# R7FA2A2AD register map
Vendor: Renesas Electronics Corporation; Series: RA2A2; File version: 1.20.02
CPU: CM23 r1p0, little endian, MPU, no FPU, VTOR, 2 interrupt priority bits, 32 interrupts
Registers are 8-bit, read-write, reset 0x0 unless marked. A register's access mark holds for its fields unless they carry their own. Offsets are from the block's base; [hi:lo] are bit positions; {n}, {i} and the like mark numbered series.

## IIC0WU — Inter,Integrated Circuit 0 Wake,up Unit
Base 0x40053014
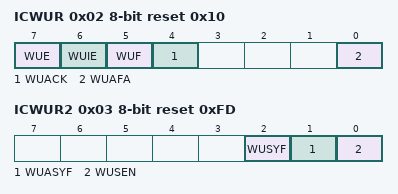
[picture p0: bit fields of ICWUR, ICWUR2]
0x02 ICWUR reset 0x10 — I2C Bus Wakeup Unit Register
  [7] WUE — Wakeup Function Enable
  [6] WUIE — Wakeup Interrupt Request Enable
  [5] WUF — Wakeup Event Occurrence Flag
  [4] WUACK — ACK Bit for Wakeup Mode
  [0] WUAFA — Wakeup Analog Filter Additional Selection
0x03 ICWUR2 reset 0xFD — I2C Bus Wakeup Unit Register 2
  [2] WUSYF ro — Wakeup Function Synchronous Operation Status Flag
  [1] WUASYF ro — Wakeup Function Asynchronous Operation Status Flag
  [0] WUSEN — Wakeup Function Synchronous Enable

## DOC — Data Operation Circuit
Base 0x40054100
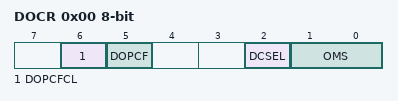
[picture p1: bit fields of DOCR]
0x00 DOCR — DOC Control Register
  [6] DOPCFCL — DOPCF Clear
  [5] DOPCF ro — DOC Flag
  [2] DCSEL — Detection Condition Select
  [1:0] OMS — Operating Mode Select
0x02 DODIR 16-bit — DOC Data Input Register
0x04 DODSR 16-bit — DOC Data Setting Register

## SPI0 — Serial Peripheral Interface
Base 0x40072000
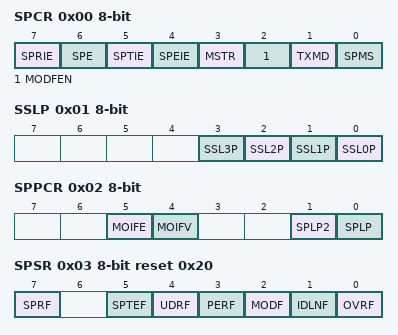
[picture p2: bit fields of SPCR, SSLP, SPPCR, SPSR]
0x00 SPCR — SPI Control Register
  [7] SPRIE — SPI Receive Buffer Full Interrupt Enable
  [6] SPE — SPI Function Enable
  [5] SPTIE — Transmit Buffer Empty Interrupt Enable
  [4] SPEIE — SPI Error Interrupt Enable
  [3] MSTR — SPI Master/Slave Mode Select
  [2] MODFEN — Mode Fault Error Detection Enable
  [1] TXMD — Communications Operating Mode Select
  [0] SPMS — SPI Mode Select
0x01 SSLP — SPI Slave Select Polarity Register
  [n] SSL{n}P (n=0..3) — SSLn{n} Signal Polarity Setting
0x02 SPPCR — SPI Pin Control Register
  [5] MOIFE — MOSI Idle Value Fixing Enable
  [4] MOIFV — MOSI Idle Fixed Value
  [1] SPLP2 — SPI Loopback 2
  [0] SPLP — SPI Loopback
0x03 SPSR reset 0x20 — SPI Status Register
  [7] SPRF — SPI Receive Buffer Full Flag
  [5] SPTEF — SPI Transmit Buffer Empty Flag
  [4] UDRF — Underrun Error Flag
  [3] PERF — Parity Error Flag
  [2] MODF — Mode Fault Error Flag
  [1] IDLNF ro — SPI Idle Flag
  [0] OVRF — Overrun Error Flag
0x04 SPDR 32-bit — SPI Data Register
0x04 SPDR_HA 16-bit (alternate view of SPDR) — SPI Data Register
0x04 SPDR_BY (alternate view of SPDR) — SPI Data Register
0x0A SPBR reset 0xFF — SPI Bit Rate Register
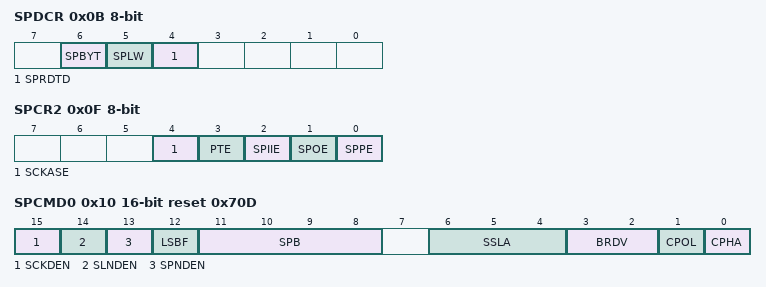
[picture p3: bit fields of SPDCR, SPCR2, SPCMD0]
0x0B SPDCR — SPI Data Control Register
  [6] SPBYT — SPI Byte Access Specification
  [5] SPLW — SPI Word Access/Halfword Access Specification
  [4] SPRDTD — SPI Receive/Transmit Data Select
0x0C SPCKD — SPI Clock Delay Register
  [2:0] SCKDL — RSPCK Delay Setting
0x0D SSLND — SPI Slave Select Negation Delay Register
  [2:0] SLNDL — SSL Negation Delay Setting
0x0E SPND — SPI Next,Access Delay Register
  [2:0] SPNDL — SPI Next,Access Delay Setting
0x0F SPCR2 — SPI Control Register 2
  [4] SCKASE — RSPCK Auto,Stop Function Enable
  [3] PTE — Parity Self,Testing
  [2] SPIIE — SPI Idle Interrupt Enable
  [1] SPOE — Parity Mode
  [0] SPPE — Parity Enable
0x10 SPCMD0 16-bit reset 0x70D — SPI Command Register 0
  [15] SCKDEN — RSPCK Delay Setting Enable
  [14] SLNDEN — SSL Negation Delay Setting Enable
  [13] SPNDEN — SPI Next,Access Delay Enable
  [12] LSBF — SPI LSB First
  [11:8] SPB — SPI Data Length Setting
  [6:4] SSLA — SSL Signal Assertion Setting
  [3:2] BRDV — Bit Rate Division Setting
  [1] CPOL — RSPCK Polarity Setting
  [0] CPHA — RSPCK Phase Setting

## CRC — Cyclic Redundancy Check Calculator
Base 0x40074000
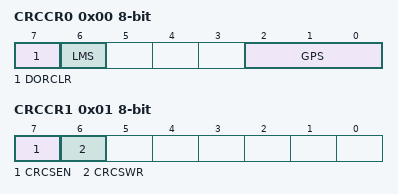
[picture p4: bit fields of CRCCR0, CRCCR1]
0x00 CRCCR0 — CRC Control Register 0
  [7] DORCLR wo — CRCDOR/CRCDOR_HA/CRCDOR_BY Register Clear
  [6] LMS — CRC Calculation Switching
  [2:0] GPS — CRC Generating Polynomial Switching
0x01 CRCCR1 — CRC Control Register 1
  [7] CRCSEN — Snoop Enable
  [6] CRCSWR — Snoop,On,Write/Read Switch
0x04 CRCDIR 32-bit — CRC Data Input Register
0x04 CRCDIR_BY (alternate view of CRCDIR) — CRC Data Input Register
0x08 CRCDOR 32-bit — CRC Data Output Register
0x08 CRCDOR_HA 16-bit (alternate view of CRCDOR) — CRC Data Output Register
0x08 CRCDOR_BY (alternate view of CRCDOR) — CRC Data Output Register
0x0C CRCSAR 16-bit — Snoop Address Register
  [13:0] CRCSA — Register Snoop Address
